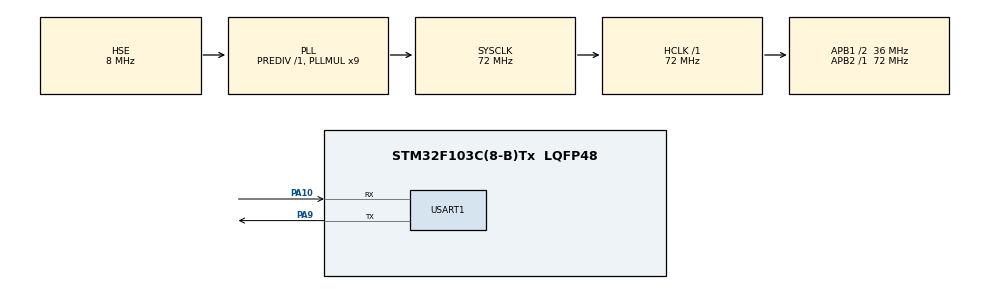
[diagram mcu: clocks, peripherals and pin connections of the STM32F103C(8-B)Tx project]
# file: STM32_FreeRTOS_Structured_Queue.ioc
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FREERTOS.Tasks01=defaultTask,0,128,StartDefaultTask,Default,NULL,Dynamic,NULL,NULL
FREERTOS.configUSE_NEWLIB_REENTRANT=1
Mcu.Family=STM32F1
Mcu.Name=STM32F103C(8-B)Tx
Mcu.Package=LQFP48
NVIC.PriorityGroup=NVIC_PRIORITYGROUP_4
NVIC.TIM3_IRQn=true\:15\:0\:false\:false\:true\:false\:false\:true\:true
NVIC.TimeBase=TIM3_IRQn
NVIC.TimeBaseIP=TIM3
NVIC.USART1_IRQn=true\:5\:0\:false\:false\:true\:true\:true\:true\:true
PA10.Mode=Asynchronous
PA10.Signal=USART1_RX
PA13.Mode=Serial_Wire
PA13.Signal=SYS_JTMS-SWDIO
PA14.Mode=Serial_Wire
PA14.Signal=SYS_JTCK-SWCLK
PA9.Mode=Asynchronous
PA9.Signal=USART1_TX
PD0-OSC_IN.Mode=HSE-External-Oscillator
PD0-OSC_IN.Signal=RCC_OSC_IN
PD1-OSC_OUT.Mode=HSE-External-Oscillator
PD1-OSC_OUT.Signal=RCC_OSC_OUT
ProjectManager.HeapSize=0x200
ProjectManager.StackSize=0x400
ProjectManager.TargetToolchain=STM32CubeIDE
RCC.AHBFreq_Value=72000000
RCC.APB1CLKDivider=RCC_HCLK_DIV2
RCC.APB1Freq_Value=36000000
RCC.APB1TimFreq_Value=72000000
RCC.APB2Freq_Value=72000000
RCC.APB2TimFreq_Value=72000000
RCC.HCLKFreq_Value=72000000
RCC.PLLMUL=RCC_PLL_MUL9
RCC.PLLSourceVirtual=RCC_PLLSOURCE_HSE
RCC.SYSCLKFreq_VALUE=72000000
RCC.SYSCLKSource=RCC_SYSCLKSOURCE_PLLCLK
RCC.USBFreq_Value=72000000
USART1.VirtualMode=VM_ASYNC
VP_FREERTOS_VS_CMSIS_V1.Mode=CMSIS_V1
VP_SYS_VS_tim3.Mode=TIM3
board=custom

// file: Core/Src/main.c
/* USER CODE BEGIN Header */
/**
 ******************************************************************************
 * @file           : main.c
 * @brief          : Main program body
 ******************************************************************************
 * @attention
 *
 * Copyright (c) 2026 STMicroelectronics.
 * All rights reserved.
 *
 * This software is licensed under terms that can be found in the LICENSE file
 * in the root directory of this software component.
 * If no LICENSE file comes with this software, it is provided AS-IS.
 *
 ******************************************************************************
 */
/* USER CODE END Header */
#include "main.h"

/* USER CODE BEGIN Includes */
#include "FreeRTOS.h"
#include "task.h"
#include "timers.h"
#include "queue.h"
#include "semphr.h"
#include "event_groups.h"

#include "string.h"
#include <stdio.h>
/* USER CODE END Includes */

UART_HandleTypeDef huart1;

void SystemClock_Config(void);
static void MX_GPIO_Init(void);
static void MX_USART1_UART_Init(void);

/* USER CODE BEGIN 0 */

// Queue Handler
xQueueHandle St_Queue_Handler;

// Tasks Handler
xTaskHandle Sender1_Task_Handler;
xTaskHandle Sender2_Task_Handler;
xTaskHandle Receiver_Task_Handler;

// Structure Definition
typedef struct
{
  char *str;
  int counter;
  uint16_t large_value;
} Structured_Struct_t;

int indx1 = 0;
int indx2 = 0;

// Function Definitions
void Sender1_Task(void *argument);
void Sender2_Task(void *argument);
void Receiver_Task(void *argument);

/* USER CODE END 0 */

int main(void)
{

  /* MCU Configuration--------------------------------------------------------*/

  /* Reset of all peripherals, Initializes the Flash interface and the Systick. */
  HAL_Init();

  /* Configure the system clock */
  SystemClock_Config();

  /* Initialize all configured peripherals */
  MX_GPIO_Init();
  MX_USART1_UART_Init();
  /* USER CODE BEGIN 2 */

  //  Create Queue
  St_Queue_Handler = xQueueCreate(2, sizeof(Structured_Struct_t));

  if(St_Queue_Handler == 0)
  {
    char *str = "Unable to create Structured queue\n\n";
    HAL_UART_Transmit(&huart1, (uint8_t*) str, strlen(str), HAL_MAX_DELAY);
  }
  else
  {
    char *str = "Structured queue Successfully Created\n\n";
    HAL_UART_Transmit(&huart1, (uint8_t*) str, strlen(str), HAL_MAX_DELAY);
  }

  // Create Tasks
  xTaskCreate(Sender1_Task, "Sender1", 128, NULL, 2, &Sender1_Task_Handler);
  xTaskCreate(Sender2_Task, "Sender2", 128, NULL, 2, &Sender2_Task_Handler);
  xTaskCreate(Receiver_Task, "Receiver", 128, NULL, 1, &Receiver_Task_Handler);

  vTaskStartScheduler();

  /* USER CODE END 2 */

  /* We should never get here as control is now taken by the scheduler */

  /* Infinite loop */
  while(1)
  {

  }
}

void SystemClock_Config(void)
{
  RCC_OscInitTypeDef RCC_OscInitStruct = {0};
  RCC_ClkInitTypeDef RCC_ClkInitStruct = {0};

  /** Initializes the RCC Oscillators according to the specified parameters
   * in the RCC_OscInitTypeDef structure.
   */
  RCC_OscInitStruct.OscillatorType = RCC_OSCILLATORTYPE_HSE;
  RCC_OscInitStruct.HSEState = RCC_HSE_ON;
  RCC_OscInitStruct.HSEPredivValue = RCC_HSE_PREDIV_DIV1;
  RCC_OscInitStruct.HSIState = RCC_HSI_ON;
  RCC_OscInitStruct.PLL.PLLState = RCC_PLL_ON;
  RCC_OscInitStruct.PLL.PLLSource = RCC_PLLSOURCE_HSE;
  RCC_OscInitStruct.PLL.PLLMUL = RCC_PLL_MUL9;
  if(HAL_RCC_OscConfig(&RCC_OscInitStruct) != HAL_OK)
  {
    Error_Handler();
  }

  /** Initializes the CPU, AHB and APB buses clocks
   */
  RCC_ClkInitStruct.ClockType = RCC_CLOCKTYPE_HCLK | RCC_CLOCKTYPE_SYSCLK | RCC_CLOCKTYPE_PCLK1 | RCC_CLOCKTYPE_PCLK2;
  RCC_ClkInitStruct.SYSCLKSource = RCC_SYSCLKSOURCE_PLLCLK;
  RCC_ClkInitStruct.AHBCLKDivider = RCC_SYSCLK_DIV1;
  RCC_ClkInitStruct.APB1CLKDivider = RCC_HCLK_DIV2;
  RCC_ClkInitStruct.APB2CLKDivider = RCC_HCLK_DIV1;

  if(HAL_RCC_ClockConfig(&RCC_ClkInitStruct, FLASH_LATENCY_2) != HAL_OK)
  {
    Error_Handler();
  }
}

static void MX_USART1_UART_Init(void)
{

  huart1.Instance = USART1;
  huart1.Init.BaudRate = 115200;
  huart1.Init.WordLength = UART_WORDLENGTH_8B;
  huart1.Init.StopBits = UART_STOPBITS_1;
  huart1.Init.Parity = UART_PARITY_NONE;
  huart1.Init.Mode = UART_MODE_TX_RX;
  huart1.Init.HwFlowCtl = UART_HWCONTROL_NONE;
  huart1.Init.OverSampling = UART_OVERSAMPLING_16;
  if(HAL_UART_Init(&huart1) != HAL_OK)
  {
    Error_Handler();
  }

}

static void MX_GPIO_Init(void)
{

  /* GPIO Ports Clock Enable */
  __HAL_RCC_GPIOD_CLK_ENABLE();
  __HAL_RCC_GPIOA_CLK_ENABLE();

}

/* USER CODE BEGIN 4 */

void Sender1_Task(void *argument)
{
  Structured_Struct_t *structptr;

  uint32_t ticks = pdMS_TO_TICKS(2000);
  while(1)
  {
    char *str = "Entered Sender1 Task\n about to send to the queue\n\n";
    HAL_UART_Transmit(&huart1, (uint8_t*) str, strlen(str), HAL_MAX_DELAY);

    // Allocated memory
    structptr = pvPortMalloc(sizeof(Structured_Struct_t));

    // Load Data
    structptr->counter = 1 + indx1;
    structptr->large_value = 1000 + indx1 * 100;
    structptr->str = "Hello From Sender1 ";

    // Send to queue
    if(xQueueSend(St_Queue_Handler, &structptr, portMAX_DELAY) == pdPASS)
    {
      char *str2 = "Successfully sent to the queue\n Leaving Sender1 Task\n\n";
      HAL_UART_Transmit(&huart1, (uint8_t*) str2, strlen(str2), HAL_MAX_DELAY);
    }

    indx1++;

    vTaskDelay(ticks);
  }
}

void Sender2_Task(void *argument)
{
  Structured_Struct_t *structptr;

  uint32_t ticks = pdMS_TO_TICKS(2000);
  while(1)
  {
    char *str = "Entered Sender2 Task\n about to send to the queue\n\n";
    HAL_UART_Transmit(&huart1, (uint8_t*) str, strlen(str), HAL_MAX_DELAY);

    // Allocated memory
    structptr = pvPortMalloc(sizeof(Structured_Struct_t));

    // Load Data
    structptr->counter = 1 + indx2;
    structptr->large_value = 2000 + indx2 * 200;
    structptr->str = "Hello From Sender2 ";

    // Send to queue
    if(xQueueSend(St_Queue_Handler, &structptr, portMAX_DELAY) == pdPASS)
    {
      char *str2 = "Successfully sent to the queue\n Leaving Sender2 Task\n\n";
      HAL_UART_Transmit(&huart1, (uint8_t*) str2, strlen(str2), HAL_MAX_DELAY);
    }

    indx2++;

    vTaskDelay(ticks);
  }
}

void Receiver_Task(void *argument)
{
  Structured_Struct_t *receiveptr;
  uint32_t ticks = pdMS_TO_TICKS(3000);
  char *ptr;
  while(1)
  {
    char *str = "Entered Receiver Task\n about to receive from the queue\n\n";
    HAL_UART_Transmit(&huart1, (uint8_t*) str, strlen(str), HAL_MAX_DELAY);

    // Receive from the queue
    if(xQueueReceive(St_Queue_Handler, &receiveptr, portMAX_DELAY) == pdPASS)
    {
      ptr = pvPortMalloc(100 * sizeof(char));

      sprintf(
          ptr,
          "Received from Queue:\n Counter = %d\n Large value = %u\n String = %s\n\n",
          receiveptr->counter,
          receiveptr->large_value,
          receiveptr->str);

      HAL_UART_Transmit(&huart1, (uint8_t*) ptr, strlen(ptr), HAL_MAX_DELAY);

      vPortFree(ptr);
    }

    vPortFree(receiveptr);   // Free the memory structure

    vTaskDelay(ticks);
  }
}

/* USER CODE END 4 */

void HAL_TIM_PeriodElapsedCallback(TIM_HandleTypeDef *htim)
{
  if(htim->Instance == TIM3)
  {
    HAL_IncTick();
  }
}

void Error_Handler(void)
{
  __disable_irq();
  while(1)
  {
  }
}
